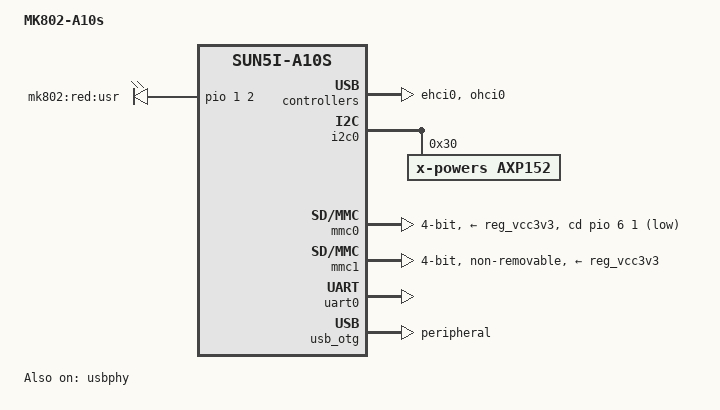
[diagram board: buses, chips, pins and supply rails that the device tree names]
/dts-v1/;
#include "sun5i-a10s.dtsi"
#include "sunxi-common-regulators.dtsi"
#include <dt-bindings/gpio/gpio.h>
/ {
	model = "MK802-A10s";
	compatible = "allwinner,a10s-mk802", "allwinner,sun5i-a10s";
	aliases {
		serial0 = &uart0;
	};
	chosen {
		stdout-path = "serial0:115200n8";
	};
	leds {
		compatible = "gpio-leds";
		led {
			label = "mk802:red:usr";
			gpios = <&pio 1 2 GPIO_ACTIVE_HIGH>;  
		};
	};
};
&ehci0 {
	status = "okay";
};
&i2c0 {
	status = "okay";
	axp152: pmic@30 {
		compatible = "x-powers,axp152";
		reg = <0x30>;
		interrupts = <0>;
		interrupt-controller;
		#interrupt-cells = <1>;
	};
};
&mmc0 {
	vmmc-supply = <&reg_vcc3v3>;
	bus-width = <4>;
	cd-gpios = <&pio 6 1 GPIO_ACTIVE_LOW>;  
	status = "okay";
};
&mmc1 {
	vmmc-supply = <&reg_vcc3v3>;
	bus-width = <4>;
	non-removable;
	status = "okay";
};
&ohci0 {
	status = "okay";
};
&otg_sram {
	status = "okay";
};
&reg_usb1_vbus {
	gpio = <&pio 1 10 GPIO_ACTIVE_HIGH>;  
	status = "okay";
};
&uart0 {
	pinctrl-names = "default";
	pinctrl-0 = <&uart0_pb_pins>;
	status = "okay";
};
&usb_otg {
	dr_mode = "peripheral";
	status = "okay";
};
&usbphy {
	usb1_vbus-supply = <&reg_usb1_vbus>;
	status = "okay";
};
